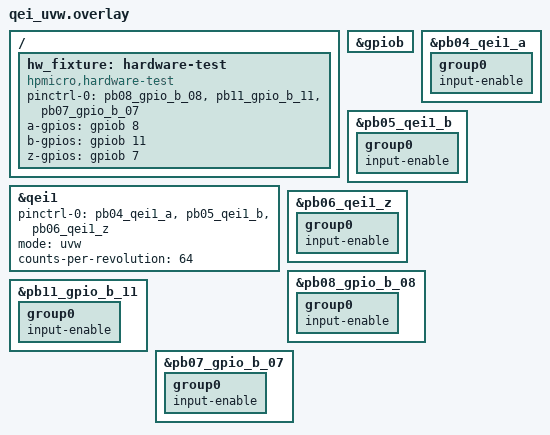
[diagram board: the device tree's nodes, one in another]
/* SPDX-License-Identifier: Apache-2.0 */

&qei1 {
	status = "okay";
	pinctrl-0 = <&pb04_qei1_a &pb05_qei1_b &pb06_qei1_z>;
	pinctrl-names = "default";
	mode = "uvw";
	counts-per-revolution = <64>;
};

/ {
	hw_fixture: hardware-test {
		compatible = "hpmicro,hardware-test";
		pinctrl-0 = <&pb08_gpio_b_08 &pb11_gpio_b_11 &pb07_gpio_b_07>;
		pinctrl-names = "default";
		a-gpios = <&gpiob 8 GPIO_ACTIVE_HIGH>;
		b-gpios = <&gpiob 11 GPIO_ACTIVE_HIGH>;
		z-gpios = <&gpiob 7 GPIO_ACTIVE_HIGH>;
	};
};

&gpiob {
	status = "okay";
};

&pb04_qei1_a {
	group0 {
		input-enable;
	};
};

&pb05_qei1_b {
	group0 {
		input-enable;
	};
};

&pb06_qei1_z {
	group0 {
		input-enable;
	};
};

&pb08_gpio_b_08 {
	group0 {
		input-enable;
	};
};

&pb11_gpio_b_11 {
	group0 {
		input-enable;
	};
};

&pb07_gpio_b_07 {
	group0 {
		input-enable;
	};
};
